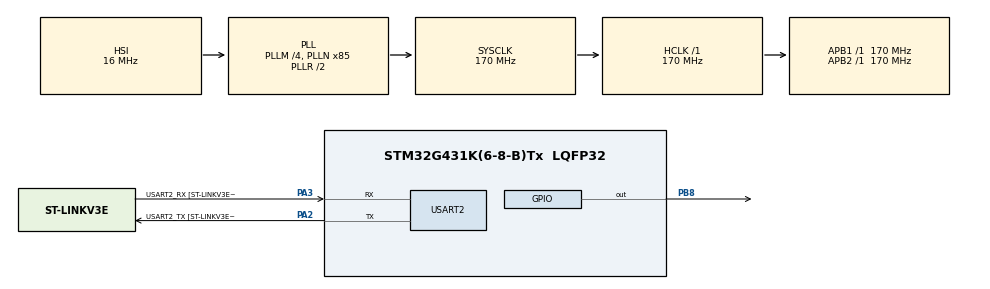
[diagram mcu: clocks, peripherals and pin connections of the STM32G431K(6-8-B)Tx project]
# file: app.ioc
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Mcu.Family=STM32G4
Mcu.Name=STM32G431K(6-8-B)Tx
Mcu.Package=LQFP32
NVIC.PriorityGroup=NVIC_PRIORITYGROUP_4
NVIC.TIM2_IRQn=true\:0\:0\:false\:false\:true\:true\:true\:true
PA13.GPIO_Label=T_SWDIO
PA13.Signal=SYS_JTMS-SWDIO
PA14.GPIO_Label=T_SWCLK
PA14.Signal=SYS_JTCK-SWCLK
PA2.GPIO_Label=USART2_TX [ST-LINKV3E_VCP_RX]
PA2.Mode=Asynchronous
PA2.Signal=USART2_TX
PA3.GPIO_Label=USART2_RX [ST-LINKV3E_VCP_TX]
PA3.Mode=Asynchronous
PA3.Signal=USART2_RX
PB3.GPIO_Label=T_SWO
PB3.Signal=SYS_JTDO-SWO
PB8-BOOT0.Signal=GPIO_Output
ProjectManager.HeapSize=0x200
ProjectManager.StackSize=0x400
ProjectManager.TargetToolchain=Makefile
RCC.ADC12Freq_Value=170000000
RCC.AHBFreq_Value=170000000
RCC.APB1Freq_Value=170000000
RCC.APB1TimFreq_Value=170000000
RCC.APB2Freq_Value=170000000
RCC.APB2TimFreq_Value=170000000
RCC.CortexFreq_Value=170000000
RCC.EXTERNAL_CLOCK_VALUE=12288000
RCC.HCLKFreq_Value=170000000
RCC.HSE_VALUE=8000000
RCC.HSI48_VALUE=48000000
RCC.HSI_VALUE=16000000
RCC.LSE_VALUE=32768
RCC.PLLM=RCC_PLLM_DIV4
RCC.PLLN=85
RCC.SYSCLKFreq_VALUE=170000000
RCC.SYSCLKSource=RCC_SYSCLKSOURCE_PLLCLK
RCC.USBFreq_Value=170000000
RCC.VCOOutputFreq_Value=340000000
TIM2.AutoReloadPreload=TIM_AUTORELOAD_PRELOAD_ENABLE
TIM2.PeriodNoDither=9999
TIM2.Prescaler=16999
USART2.VirtualMode-Asynchronous=VM_ASYNC
VP_SYS_VS_DBSignals.Mode=DisableDeadBatterySignals
VP_TIM2_VS_ClockSourceINT.Mode=Internal
board=NUCLEO-G431KB

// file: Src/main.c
/* USER CODE BEGIN Header */
/**
  ******************************************************************************
  * @file           : main.c
  * @brief          : Main program body
  ******************************************************************************
  * @attention
  *
  * Copyright (c) 2026 STMicroelectronics.
  * All rights reserved.
  *
  * This software is licensed under terms that can be found in the LICENSE file
  * in the root directory of this software component.
  * If no LICENSE file comes with this software, it is provided AS-IS.
  *
  ******************************************************************************
  */
/* USER CODE END Header */
#include "main.h"

/* USER CODE BEGIN Includes */
#include "image_header.h"
#include "g4b_log.h"
#include "g4b_state.h"
#include <stdarg.h>
/* USER CODE END Includes */

TIM_HandleTypeDef htim2;

UART_HandleTypeDef huart2;

/* USER CODE BEGIN PV */
/* Survives a warm reset -- app writes G4B_BOOT_MAGIC_STAY here and resets to
   ask the bootloader to stay put. Same address in bl, app_a and app_b. */
__attribute__((section(".noinit"))) uint32_t g4b_boot_request;
/* USER CODE END PV */

void SystemClock_Config(void);
static void MX_GPIO_Init(void);
static void MX_USART2_UART_Init(void);
static void MX_TIM2_Init(void);

/* USER CODE BEGIN 0 */
void g4b_printf(const char *fmt, ...)
{
  char buf[160];
  char *p = buf;
  char *const end = buf + sizeof buf;
  va_list ap;
  va_start(ap, fmt);

  for (const char *f = fmt; *f != '\0' && p < end; f++) {
    if (*f != '%') { *p++ = *f; continue; }

    f++;                                        /* past '%' */
    unsigned pad = 0u;                          /* "08" -> 8; only zero-pad */
    while (*f >= '0' && *f <= '9') { pad = pad * 10u + (unsigned)(*f - '0'); f++; }
    while (*f == 'l' || *f == 'h') { f++; }     /* accept, ignore: all 32-bit */

    char tmp[10];
    unsigned n = 0u;
    unsigned long v;

    switch (*f) {
    case 's': {
      const char *s = va_arg(ap, const char *);
      while (*s != '\0' && p < end) { *p++ = *s++; }
      break;
    }
    case 'x':
    case 'X': {
      const char *digits = (*f == 'X') ? "0123456789ABCDEF" : "0123456789abcdef";
      v = va_arg(ap, unsigned long);
      do { tmp[n++] = digits[v & 0xFuL]; v >>= 4; } while (v != 0uL && n < sizeof tmp);
      while (n < pad && n < sizeof tmp) { tmp[n++] = '0'; }
      while (n > 0u && p < end) { *p++ = tmp[--n]; }
      break;
    }
    case 'u': {
      v = va_arg(ap, unsigned long);
      do { tmp[n++] = (char)('0' + (v % 10uL)); v /= 10uL; } while (v != 0uL && n < sizeof tmp);
      while (n < pad && n < sizeof tmp) { tmp[n++] = '0'; }
      while (n > 0u && p < end) { *p++ = tmp[--n]; }
      break;
    }
    case '%':   *p++ = '%'; break;
    case '\0':  f--;        break;              /* trailing '%': let the loop end */
    default:    *p++ = *f;  break;              /* unknown: emit it literally */
    }
  }

  va_end(ap);
  HAL_UART_Transmit(&huart2, (uint8_t *)buf, (uint16_t)(p - buf), HAL_MAX_DELAY);
}

/* Fires at 1 Hz from TIM2. A delay loop here would prove nothing about
   interrupt delivery, which is the whole point of the exercise. */
void HAL_TIM_PeriodElapsedCallback(TIM_HandleTypeDef *htim)
{
  if (htim->Instance == TIM2) {
    HAL_GPIO_TogglePin(GPIOB, GPIO_PIN_8);
  }
}
/* USER CODE END 0 */

int main(void)
{

  /* USER CODE BEGIN 1 */
  /* Assert our own vector table rather than inheriting whatever the bootloader
     left in VTOR. g_pfnVectors comes from startup_stm32g431xx.s, so this is
     correct in both slot variants with no per-slot #define. */
  extern uint32_t g_pfnVectors;
  SCB->VTOR = (uint32_t)&g_pfnVectors;
  /* USER CODE END 1 */

  /* MCU Configuration--------------------------------------------------------*/

  /* Reset of all peripherals, Initializes the Flash interface and the Systick. */
  HAL_Init();

  /* Configure the system clock */
  SystemClock_Config();

  /* Initialize all configured peripherals */
  MX_GPIO_Init();
  MX_USART2_UART_Init();
  MX_TIM2_Init();
  /* USER CODE BEGIN 2 */
  g4b_printf("G4Boot app 0.1.0  vtor 0x%08lX  %s %s\r\n",
             (unsigned long)SCB->VTOR, __DATE__, __TIME__);
  HAL_TIM_Base_Start_IT(&htim2);

  #ifdef G4B_SIMULATE_HANG
    g4b_printf("simulating a hang: no kick, no confirm\r\n");
    for (;;) { }
  #endif

  g4b_crc_init();

  boot_state_t st;
  uint32_t stale;
  if (g4b_state_load(&st, &stale)) {
    uint8_t me = (SCB->VTOR == G4B_SLOT_B_APP_BASE) ? G4B_SLOT_B : G4B_SLOT_A;

    if (st.pending == me) {
      /* Tentative boot. Healthy, for this bench app, means alive this long;
         real firmware runs its own checks before vouching for itself. */
      HAL_Delay(2000u);
      if (g4b_state_write(stale, me, G4B_SLOT_NONE, 0u, 1u, st.seq + 1u)) {
        g4b_printf("confirmed slot %s\r\n", (me == G4B_SLOT_B) ? "B" : "A");
      }
    }
  }
  /* USER CODE END 2 */

  /* Infinite loop */
  /* USER CODE BEGIN WHILE */
  while (1)
  {
    IWDG->KR = 0xAAAAu;
    /* USER CODE END WHILE */

  }
}

void SystemClock_Config(void)
{
  RCC_OscInitTypeDef RCC_OscInitStruct = {0};
  RCC_ClkInitTypeDef RCC_ClkInitStruct = {0};

  /** Configure the main internal regulator output voltage
  */
  HAL_PWREx_ControlVoltageScaling(PWR_REGULATOR_VOLTAGE_SCALE1_BOOST);

  /** Initializes the RCC Oscillators according to the specified parameters
  * in the RCC_OscInitTypeDef structure.
  */
  RCC_OscInitStruct.OscillatorType = RCC_OSCILLATORTYPE_HSI;
  RCC_OscInitStruct.HSIState = RCC_HSI_ON;
  RCC_OscInitStruct.HSICalibrationValue = RCC_HSICALIBRATION_DEFAULT;
  RCC_OscInitStruct.PLL.PLLState = RCC_PLL_ON;
  RCC_OscInitStruct.PLL.PLLSource = RCC_PLLSOURCE_HSI;
  RCC_OscInitStruct.PLL.PLLM = RCC_PLLM_DIV4;
  RCC_OscInitStruct.PLL.PLLN = 85;
  RCC_OscInitStruct.PLL.PLLP = RCC_PLLP_DIV2;
  RCC_OscInitStruct.PLL.PLLQ = RCC_PLLQ_DIV2;
  RCC_OscInitStruct.PLL.PLLR = RCC_PLLR_DIV2;
  if (HAL_RCC_OscConfig(&RCC_OscInitStruct) != HAL_OK)
  {
    Error_Handler();
  }

  /** Initializes the CPU, AHB and APB buses clocks
  */
  RCC_ClkInitStruct.ClockType = RCC_CLOCKTYPE_HCLK|RCC_CLOCKTYPE_SYSCLK
                              |RCC_CLOCKTYPE_PCLK1|RCC_CLOCKTYPE_PCLK2;
  RCC_ClkInitStruct.SYSCLKSource = RCC_SYSCLKSOURCE_PLLCLK;
  RCC_ClkInitStruct.AHBCLKDivider = RCC_SYSCLK_DIV1;
  RCC_ClkInitStruct.APB1CLKDivider = RCC_HCLK_DIV1;
  RCC_ClkInitStruct.APB2CLKDivider = RCC_HCLK_DIV1;

  if (HAL_RCC_ClockConfig(&RCC_ClkInitStruct, FLASH_LATENCY_4) != HAL_OK)
  {
    Error_Handler();
  }
}

static void MX_TIM2_Init(void)
{

  TIM_ClockConfigTypeDef sClockSourceConfig = {0};
  TIM_MasterConfigTypeDef sMasterConfig = {0};

  htim2.Instance = TIM2;
  htim2.Init.Prescaler = 16999;
  htim2.Init.CounterMode = TIM_COUNTERMODE_UP;
  htim2.Init.Period = 9999;
  htim2.Init.ClockDivision = TIM_CLOCKDIVISION_DIV1;
  htim2.Init.AutoReloadPreload = TIM_AUTORELOAD_PRELOAD_ENABLE;
  if (HAL_TIM_Base_Init(&htim2) != HAL_OK)
  {
    Error_Handler();
  }
  sClockSourceConfig.ClockSource = TIM_CLOCKSOURCE_INTERNAL;
  if (HAL_TIM_ConfigClockSource(&htim2, &sClockSourceConfig) != HAL_OK)
  {
    Error_Handler();
  }
  sMasterConfig.MasterOutputTrigger = TIM_TRGO_RESET;
  sMasterConfig.MasterSlaveMode = TIM_MASTERSLAVEMODE_DISABLE;
  if (HAL_TIMEx_MasterConfigSynchronization(&htim2, &sMasterConfig) != HAL_OK)
  {
    Error_Handler();
  }

}

static void MX_USART2_UART_Init(void)
{

  huart2.Instance = USART2;
  huart2.Init.BaudRate = 115200;
  huart2.Init.WordLength = UART_WORDLENGTH_8B;
  huart2.Init.StopBits = UART_STOPBITS_1;
  huart2.Init.Parity = UART_PARITY_NONE;
  huart2.Init.Mode = UART_MODE_TX_RX;
  huart2.Init.HwFlowCtl = UART_HWCONTROL_NONE;
  huart2.Init.OverSampling = UART_OVERSAMPLING_16;
  huart2.Init.OneBitSampling = UART_ONE_BIT_SAMPLE_DISABLE;
  huart2.Init.ClockPrescaler = UART_PRESCALER_DIV1;
  huart2.AdvancedInit.AdvFeatureInit = UART_ADVFEATURE_NO_INIT;
  if (HAL_UART_Init(&huart2) != HAL_OK)
  {
    Error_Handler();
  }
  if (HAL_UARTEx_SetTxFifoThreshold(&huart2, UART_TXFIFO_THRESHOLD_1_8) != HAL_OK)
  {
    Error_Handler();
  }
  if (HAL_UARTEx_SetRxFifoThreshold(&huart2, UART_RXFIFO_THRESHOLD_1_8) != HAL_OK)
  {
    Error_Handler();
  }
  if (HAL_UARTEx_DisableFifoMode(&huart2) != HAL_OK)
  {
    Error_Handler();
  }

}

static void MX_GPIO_Init(void)
{
  GPIO_InitTypeDef GPIO_InitStruct = {0};

  /* GPIO Ports Clock Enable */
  __HAL_RCC_GPIOA_CLK_ENABLE();
  __HAL_RCC_GPIOB_CLK_ENABLE();

  /*Configure GPIO pin Output Level */
  HAL_GPIO_WritePin(GPIOB, GPIO_PIN_8, GPIO_PIN_RESET);

  /*Configure GPIO pin : PB8 */
  GPIO_InitStruct.Pin = GPIO_PIN_8;
  GPIO_InitStruct.Mode = GPIO_MODE_OUTPUT_PP;
  GPIO_InitStruct.Pull = GPIO_NOPULL;
  GPIO_InitStruct.Speed = GPIO_SPEED_FREQ_LOW;
  HAL_GPIO_Init(GPIOB, &GPIO_InitStruct);

}

void Error_Handler(void)
{
  __disable_irq();
  while (1)
  {
  }
}
